# I2C2_1.0 register map
Vendor: Texas Instruments
Registers are 32-bit, read-write, no defined reset value unless marked. A register's access mark holds for its fields unless they carry their own. Offsets are as the file gives them; [hi:lo] are bit positions; lines under a group give offsets from that group; {n}, {i} and the like mark numbered series; 'fields as' and 'values as' point back to an identical list; <NAME> marks a mode.

## I2C2 (part 2 of 2)
0x800 I2C2_GPRCM group
  0x00 I2C2_PWREN — Power enable
    [0] ENABLE — Enable the power
      0=DISABLE (Disable Power); 1=ENABLE (Enable Power)
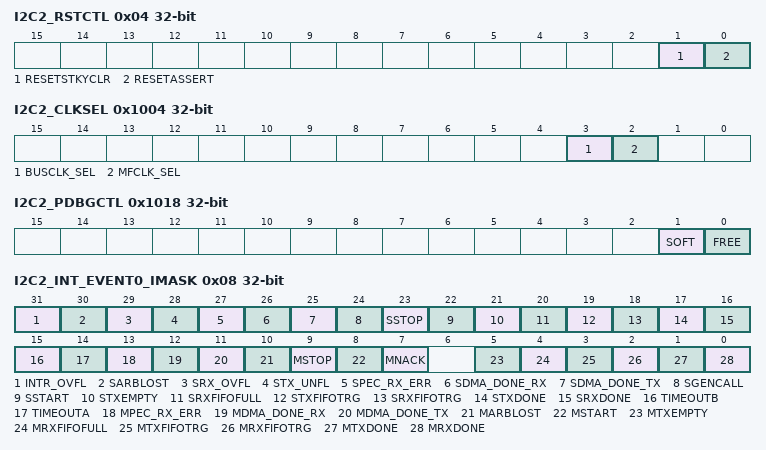
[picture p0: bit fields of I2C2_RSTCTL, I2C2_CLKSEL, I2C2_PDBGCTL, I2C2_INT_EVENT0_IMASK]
  0x04 I2C2_RSTCTL — Reset Control
    [1] RESETSTKYCLR — Clear the RESETSTKY bit in the STAT register
      0=NOP (Writing 0 has no effect); 1=CLR (Clear reset sticky bit)
    [0] RESETASSERT — Assert reset to the peripheral
      0=NOP (Writing 0 has no effect); 1=ASSERT (Assert reset)
  0x08 I2C2_CLKCFG — Peripheral Clock Configuration Register
    [8] BLOCKASYNC — Async Clock Request is blocked from starting SYSOSC or forcing bus clock to 32MHz
      0=DISABLE (Not block async clock request); 1=ENABLE (Block async clock request)
  0x14 I2C2_STAT ro — Status Register
    [16] RESETSTKY — This bit indicates, if the peripheral was reset, since this bit was cleared by RESETSTKYCLR in the RSTCTL register
      0=NORES (The peripheral has not been reset since this bit was last cleared by RESETSTKYCLR in the RSTCTL register); 1=RESET (The peripheral was reset since the last bit clear)
0x1000 I2C2_CLKDIV — Clock Divider
  [2:0] RATIO — Selects divide ratio of module clock
    0=DIV_BY_1 (Do not divide clock source); {v}=DIV_BY_{v+1} (Divide clock source by {v+1}) (v=1..7)
0x1004 I2C2_CLKSEL — Clock Select for Ultra Low Power peripherals
  [3] BUSCLK_SEL — Selects BUSCLK as clock source if enabled
    0=DISABLE (Does not select this clock as a source); 1=ENABLE (Select this clock as a source)
  [2] MFCLK_SEL — Selects MFCLK as clock source if enabled
    values as BUSCLK_SEL
0x1018 I2C2_PDBGCTL — Peripheral Debug Control
  [1] SOFT — Soft halt boundary control. This function is only available, if [FREE] is set to 'STOP'
    0=IMMEDIATE (The peripheral will halt immediately, even if the resultant state will result in corruption if the system is restarted); 1=DELAYED (The peripheral blocks the debug freeze until it has reached a boundary where it can resume without corruption)
  [0] FREE — Free run control
    0=STOP (The peripheral freezes functionality while the Core Halted input is asserted and resumes when it is deasserted.); 1=RUN (The peripheral ignores the state of the Core Halted input)
0x1020 I2C2_INT_EVENT0 group
  0x00 I2C2_INT_EVENT0_IIDX ro — Interrupt index
    [7:0] STAT — I2C Module Interrupt Vector Value. This register provides the highes priority interrupt index. A read clears the corresponding interrupt flag in RIS and MISC. 15h-1Fh = Reserved
      0=NO_INTR (No interrupt pending); 1=MRXDONEFG (Master data received); 2=MTXDONEFG (Master data transmitted); 3=MRXFIFOTRG (Master receive FIFO Trigger Level); 4=MTXFIFOTRG (Master transmit FIFO Trigger level); 5=MRXFIFOFULL (RX FIFO FULL Event/interrupt pending); 6=MTX_EMPTY (Transmit FIFO/Buffer Empty Event/interrupt pending); 8=MNACKFG (Address/Data NACK); 9=MSTARTFG (Start Event); 10=MSTOPFG (Stop Event); 11=MARBLOSTFG (Arbitration Lost); 12=MDMA_DONE_TX (DMA DONE on Channel TX); 13=MDMA_DONE_RX (DMA DONE on Channel RX); 14=MPEC_RX_ERR (Master PEC Receive Error Event); 15=TIMEOUTA (Timeout A Event); 16=TIMEOUTB (Timeout B Event); 17=SRXDONEFG (Slave Data Event); 18=STXDONEFG (Slave Data Event); 19=SRXFIFOTRG (Slave receive FIFO Trigger Level); 20=STXFIFOTRG (Slave transmit FIFO Trigger level); 21=SRXFIFOFULL (RX FIFO FULL Event/interrupt pending); 22=STXEMPTY (Transmit FIFO/Buffer Empty Event/interrupt pending); 23=SSTARTFG (Start Event); 24=SSTOPFG (Stop Event); 25=SGENCALL (General Call Event); 26=SDMA_DONE_TX (DMA DONE on Channel TX); 27=SDMA_DONE_RX (DMA DONE on Channel RX); 28=SPEC_RX_ERR (Slave PEC receive error event); 29=STX_UNFL (Slave TX FIFO underflow); 30=SRX_OVFL (Slave RX FIFO overflow event); 31=SARBLOST (Slave arbitration lost event); 32=INTR_OVFL (Interrupt overflow event)
  0x08 I2C2_INT_EVENT0_IMASK — Interrupt mask
    [31] INTR_OVFL — Interrupt Overflow Interrupt Mask
      0=CLR (Clear Interrupt Mask); 1=SET (Set Interrupt Mask)
    [30] SARBLOST — Slave Arbitration Lost
      0=CLR (Clear Set Interrupt Mask); 1=SET (Set Interrupt Mask)
    [29] SRX_OVFL — Slave RX FIFO overflow
      0=CLR (Clear Interrupt Mask); 1=SET (Set Interrupt Mask)
    [28] STX_UNFL — Slave TX FIFO underflow
      0=CLR (Clear Interrupt Mask); 1=SET (Set Interrupt Mask)
    [27] SPEC_RX_ERR — Slave RX Pec Error Interrupt
      0=CLR (Clear Interrupt Mask); 1=SET (Set Interrupt Mask)
    [26] SDMA_DONE_RX — Slave DMA Done on Event Channel RX
      0=CLR (Clear Interrupt Mask); 1=SET (Set Interrupt Mask)
    [25] SDMA_DONE_TX — Slave DMA Done on Event Channel TX
      0=CLR (Clear Interrupt Mask); 1=SET (Set Interrupt Mask)
    [24] SGENCALL — General Call Interrupt
      0=CLR (Clear Interrupt Mask); 1=SET (Set Interrupt Mask)
    [23] SSTOP — Stop Condition Interrupt
      0=CLR (Clear Interrupt Mask); 1=SET (Set Interrupt Mask)
    [22] SSTART — Start Condition Interrupt
      0=CLR (Clear Interrupt Mask); 1=SET (Set Interrupt Mask)
    [21] STXEMPTY — Slave Transmit FIFO Empty interrupt mask. This interrupt is set if all data in the Transmit FIFO have been shifted out and the transmit goes into idle mode.
      0=CLR (Clear Interrupt Mask); 1=SET (Set Interrupt Mask)
    [20] SRXFIFOFULL — RXFIFO full event. This interrupt is set if an Slave RX FIFO is full.
      0=CLR (Clear Interrupt Mask); 1=SET (Set Interrupt Mask)
    [19] STXFIFOTRG — Slave Transmit FIFO Trigger
      0=CLR (Clear Interrupt Mask); 1=SET (Set Interrupt Mask)
    [18] SRXFIFOTRG — Slave Receive FIFO Trigger
      0=CLR (Clear Interrupt Mask); 1=SET (Set Interrupt Mask)
    [17] STXDONE — Slave Transmit Transaction completed Interrupt
      0=CLR (Clear Interrupt Mask); 1=SET (Set Interrupt Mask)
    [16] SRXDONE — Slave Receive Data Interrupt Signals that a byte has been received
      0=CLR (Clear Interrupt Mask); 1=SET (Set Interrupt Mask)
    [15] TIMEOUTB — Timeout B Interrupt
      0=CLR (Clear Interrupt Mask); 1=SET (Set Interrupt Mask)
    [14] TIMEOUTA — Timeout A Interrupt
      0=CLR (Clear Interrupt Mask); 1=SET (Set Interrupt Mask)
    [13] MPEC_RX_ERR — Master RX Pec Error Interrupt
      0=CLR (Clear Interrupt Mask); 1=SET (Set Interrupt Mask)
    [12] MDMA_DONE_RX — DMA Done on Event Channel RX
      0=CLR (Interrupt disabled); 1=SET (Set Interrupt Mask)
    [11] MDMA_DONE_TX — DMA Done on Event Channel TX
      0=CLR (Interrupt disabled); 1=SET (Set Interrupt Mask)
    [10] MARBLOST — Arbitration Lost Interrupt
      0=CLR (Clear Interrupt Mask); 1=SET (Set Interrupt Mask)
    [9] MSTOP — STOP Detection Interrupt
      0=CLR (Clear Interrupt Mask); 1=SET (Set Interrupt Mask)
    [8] MSTART — START Detection Interrupt
      0=CLR (Clear Interrupt Mask); 1=SET (Set Interrupt Mask)
    [7] MNACK — Address/Data NACK Interrupt
      0=CLR (Clear Interrupt Mask); 1=SET (Set Interrupt Mask)
    [5] MTXEMPTY — Transmit FIFO Empty interrupt mask. This interrupt is set if all data in the Transmit FIFO have been shifted out and the transmit goes into idle mode.
      0=CLR (Clear Interrupt Mask); 1=SET (Set Interrupt Mask)
    [4] MRXFIFOFULL — RXFIFO full event. This interrupt is set if an RX FIFO is full.
      0=CLR (Clear Interrupt Mask); 1=SET (Set Interrupt Mask)
    [3] MTXFIFOTRG — Master Transmit FIFO Trigger Trigger when Transmit FIFO contains <= defined bytes
      0=CLR (Clear Interrupt Mask); 1=SET (Set Interrupt Mask)
    [2] MRXFIFOTRG — Master Receive FIFO Trigger Trigger when RX FIFO contains >= defined bytes
      0=CLR (Clear Interrupt Mask); 1=SET (Set Interrupt Mask)
    [1] MTXDONE — Master Transmit Transaction completed Interrupt
      0=CLR (Clear Interrupt Mask); 1=SET (Set Interrupt Mask)
    [0] MRXDONE — Master Receive Transaction completed Interrupt
      0=CLR (Clear Interrupt Mask); 1=SET (Set Interrupt Mask)
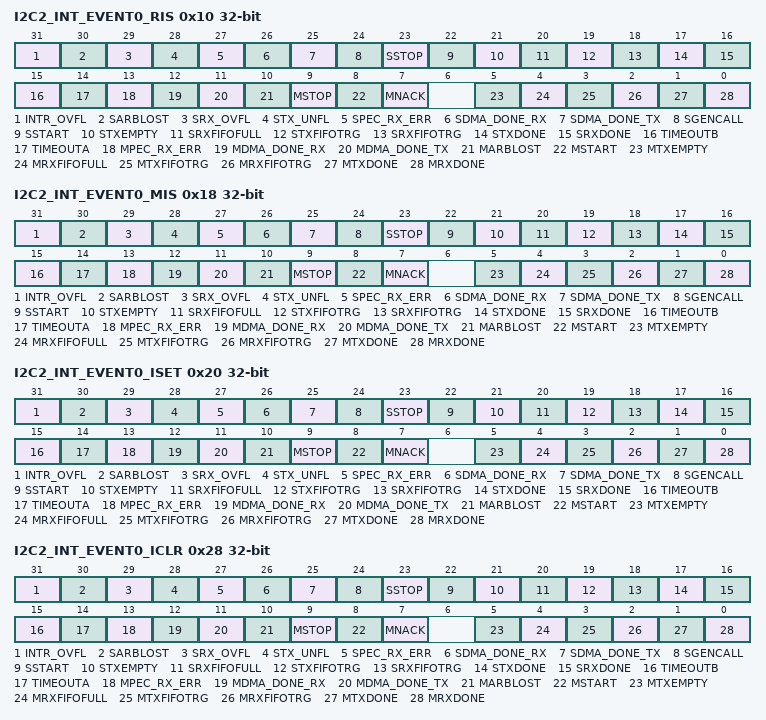
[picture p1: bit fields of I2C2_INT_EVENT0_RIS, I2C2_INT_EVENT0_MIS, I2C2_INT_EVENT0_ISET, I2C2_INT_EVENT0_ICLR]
  0x10 I2C2_INT_EVENT0_RIS — Raw interrupt status
    [31] INTR_OVFL — Interrupt overflow interrupt It is set when SSTART or SSTOP interrupts overflow i.e. occur twice without being serviced
      0=CLR (Interrupt did not occur); 1=SET (Interrupt occured)
    [30] SARBLOST — Slave Arbitration Lost
      0=CLR (Interrupt did not occur); 1=SET (Interrupt occured)
    [29] SRX_OVFL — Slave RX FIFO overflow
      0=CLR (Interrupt did not occur); 1=SET (Interrupt Occured)
    [28] STX_UNFL — Slave TX FIFO underflow
      0=CLR (Interrupt did not occur); 1=SET (Interrupt occured)
    [27] SPEC_RX_ERR — Slave RX Pec Error Interrupt
      0=CLR (Interrupt did not occur); 1=SET (Interrupt ocuured)
    [26] SDMA_DONE_RX — DMA Done on Event Channel RX
      0=CLR (Clear interrupt); 1=SET (Set interrupt)
    [25] SDMA_DONE_TX — DMA Done on Event Channel TX
      0=CLR (Clear interrupt); 1=SET (Set interrupt)
    [24] SGENCALL — General Call Interrupt
      0=CLR (Clear Interrupt Mask); 1=SET (Set Interrupt Mask)
    [23] SSTOP — Stop Condition Interrupt
      0=CLR (Clear Interrupt); 1=SET (Set interrupt)
    [22] SSTART — Start Condition Interrupt
      0=CLR (Clear interrupt); 1=SET (Set Interrupt)
    [21] STXEMPTY — Transmit FIFO Empty interrupt mask. This interrupt is set if all data in the Transmit FIFO have been shifted out and the transmit goes into idle mode.
      0=CLR (Interrupt did not occur); 1=SET (Set Interrupt Mask)
    [20] SRXFIFOFULL — RXFIFO full event. This interrupt is set if an RX FIFO is full.
      0=CLR (Clear Interrupt Mask); 1=SET (Set Interrupt Mask)
    [19] STXFIFOTRG — Slave Transmit FIFO Trigger
      0=CLR (Clear Interrupt Mask); 1=SET (Set Interrupt Mask)
    [18] SRXFIFOTRG — Slave Receive FIFO Trigger
      0=CLR (Clear Interrupt Mask); 1=SET (Set Interrupt Mask)
    [17] STXDONE — Slave Transmit Transaction completed Interrupt
      0=CLR (Interrupt did not occur); 1=SET (Set Interrupt Mask)
    [16] SRXDONE — Slave Receive Data Interrupt Signals that a byte has been received
      0=CLR (Interrupt did not occur); 1=SET (Set Interrupt Mask)
    [15] TIMEOUTB — Timeout B Interrupt
      0=CLR (Interrupt did not occur); 1=SET (Interrupt occured)
    [14] TIMEOUTA — Timeout A Interrupt
      0=CLR (Interrupt did not occur); 1=SET (Set Interrupt Mask)
    [13] MPEC_RX_ERR — Master RX Pec Error Interrupt
      0=CLR (Interrupt did not occur); 1=SET (Interrupt Occured)
    [12] MDMA_DONE_RX — DMA Done on Event Channel RX
      0=CLR (Interrupt disabled); 1=SET (Set Interrupt Mask)
    [11] MDMA_DONE_TX — DMA Done on Event Channel TX
      0=CLR (Interrupt disabled); 1=SET (Set Interrupt Mask)
    [10] MARBLOST — Arbitration Lost Interrupt
      0=CLR (Interrupt did not occur); 1=SET (Set Interrupt Mask)
    [9] MSTOP — STOP Detection Interrupt
      0=CLR (Interrupt did not occur); 1=SET (Set Interrupt Mask)
    [8] MSTART — START Detection Interrupt
      0=CLR (Interrupt did not occur); 1=SET (Set Interrupt Mask)
    [7] MNACK — Address/Data NACK Interrupt
      0=CLR (Interrupt did not occur); 1=SET (Set Interrupt Mask)
    [5] MTXEMPTY — Transmit FIFO Empty interrupt mask. This interrupt is set if all data in the Transmit FIFO have been shifted out and the transmit goes into idle mode.
      0=CLR (Interrupt did not occur); 1=SET (Set Interrupt Mask)
    [4] MRXFIFOFULL — RXFIFO full event. This interrupt is set if an RX FIFO is full.
      0=CLR (Interrupt did not occur); 1=SET (Set Interrupt Mask)
    [3] MTXFIFOTRG — Master Transmit FIFO Trigger Trigger when Transmit FIFO contains <= defined bytes
      0=CLR (Clear Interrupt Mask); 1=SET (Set Interrupt Mask)
    [2] MRXFIFOTRG — Master Receive FIFO Trigger Trigger when RX FIFO contains >= defined bytes
      0=CLR (Clear Interrupt Mask); 1=SET (Set Interrupt Mask)
    [1] MTXDONE — Master Transmit Transaction completed Interrupt
      0=CLR (Interrupt did not occur); 1=SET (Set Interrupt Mask)
    [0] MRXDONE — Master Receive Transaction completed Interrupt
      0=CLR (Interrupt did not occur); 1=SET (Set Interrupt Mask)
  0x18 I2C2_INT_EVENT0_MIS — Masked interrupt status
    [31] INTR_OVFL — Interrupt overflow
      0=CLR (Interrupt did not occur); 1=SET (Interrupt occured)
    [30] SARBLOST — Slave Arbitration Lost
      0=CLR (Clear interrupt mask); 1=SET (Set interrupt mask)
    [29] SRX_OVFL — Slave RX FIFO overflow
      0=CLR (Clear interrupt mask); 1=SET (Set interrupt mask)
    [28] STX_UNFL — Slave TX FIFO underflow
      0=CLR (Clear interrupt mask); 1=SET (Set interrupt mask)
    [27] SPEC_RX_ERR — Slave RX Pec Error Interrupt
      0=CLR (Clear interrupt mask); 1=SET (Set interrupt mask)
    [26] SDMA_DONE_RX — DMA Done on Event Channel RX
      0=CLR (Clear MIS); 1=SET (Set MIS)
    [25] SDMA_DONE_TX — DMA Done on Event Channel TX
      0=CLR (Clear MIS); 1=SET (Set MIS)
    [24] SGENCALL — General Call Interrupt
      0=CLR (Interrupt did not occur); 1=SET (Set Interrupt Mask)
    [23] SSTOP — Slave STOP Detection Interrupt
      0=CLR (Clear MIS); 1=SET (Set MIS)
    [22] SSTART — Slave START Detection Interrupt
      0=CLR (Clear MIS); 1=SET (Set MIS)
    [21] STXEMPTY — Transmit FIFO Empty interrupt mask. This interrupt is set if all data in the Transmit FIFO have been shifted out and the transmit goes into idle mode.
      0=CLR (Interrupt did not occur); 1=SET (Set Interrupt Mask)
    [20] SRXFIFOFULL — RXFIFO full event. This interrupt is set if an RX FIFO is full.
      0=CLR (Clear Interrupt Mask); 1=SET (Set Interrupt Mask)
    [19] STXFIFOTRG — Slave Transmit FIFO Trigger
      0=CLR (Clear Interrupt Mask); 1=SET (Set Interrupt Mask)
    [18] SRXFIFOTRG — Slave Receive FIFO Trigger
      0=CLR (Clear Interrupt Mask); 1=SET (Set Interrupt Mask)
    [17] STXDONE — Slave Transmit Transaction completed Interrupt
      0=CLR (Interrupt did not occur); 1=SET (Set Interrupt Mask)
    [16] SRXDONE — Slave Receive Data Interrupt Signals that a byte has been received
      0=CLR (Interrupt did not occur); 1=SET (Set Interrupt Mask)
    [15] TIMEOUTB — Timeout B Interrupt
      0=CLR (Clear interrupt mask); 1=SET (Set interrupt mask)
    [14] TIMEOUTA — Timeout A Interrupt
      0=CLR (Interrupt did not occur); 1=SET (Set Interrupt Mask)
    [13] MPEC_RX_ERR — Master RX Pec Error Interrupt
      0=CLR (Clear interrupt mask); 1=SET (Set interrupt mask)
    [12] MDMA_DONE_RX — DMA Done on Event Channel RX
      0=CLR (Interrupt disabled); 1=SET (Set Interrupt Mask)
    [11] MDMA_DONE_TX — DMA Done on Event Channel TX
      0=CLR (Interrupt disabled); 1=SET (Set Interrupt Mask)
    [10] MARBLOST — Arbitration Lost Interrupt
      0=CLR (Interrupt did not occur); 1=SET (Set Interrupt Mask)
    [9] MSTOP — STOP Detection Interrupt
      0=CLR (Interrupt did not occur); 1=SET (Set Interrupt Mask)
    [8] MSTART — START Detection Interrupt
      0=CLR (Interrupt did not occur); 1=SET (Set Interrupt Mask)
    [7] MNACK — Address/Data NACK Interrupt
      0=CLR (Interrupt did not occur); 1=SET (Set Interrupt Mask)
    [5] MTXEMPTY — Transmit FIFO Empty interrupt mask. This interrupt is set if all data in the Transmit FIFO have been shifted out and the transmit goes into idle mode.
      0=CLR (Interrupt did not occur); 1=SET (Set Interrupt Mask)
    [4] MRXFIFOFULL — RXFIFO full event. This interrupt is set if the RX FIFO is full.
      0=CLR (Interrupt did not occur); 1=SET (Set Interrupt Mask)
    [3] MTXFIFOTRG — Master Transmit FIFO Trigger Trigger when Transmit FIFO contains <= defined bytes
      0=CLR (Clear Interrupt Mask); 1=SET (Set Interrupt Mask)
    [2] MRXFIFOTRG — Master Receive FIFO Trigger Trigger when RX FIFO contains >= defined bytes
      0=CLR (Clear Interrupt Mask); 1=SET (Set Interrupt Mask)
    [1] MTXDONE — Master Transmit Transaction completed Interrupt
      0=CLR (Interrupt did not occur); 1=SET (Set Interrupt Mask)
    [0] MRXDONE — Master Receive Data Interrupt
      0=CLR (Interrupt did not occur); 1=SET (Set Interrupt Mask)
  0x20 I2C2_INT_EVENT0_ISET — Interrupt set
    [31] INTR_OVFL — Interrupt overflow
      0=NO_EFFECT; 1=SET (Set interrupt)
    [30] SARBLOST — Slave Arbitration Lost
      0=NO_EFFECT (Writing 0 has no effect); 1=SET (Set interrupt)
    [29] SRX_OVFL — Slave RX FIFO overflow
      0=NO_EFFECT (Writing 0 has no effect); 1=SET (Set interrupt)
    [28] STX_UNFL — Slave TX FIFO underflow
      0=NO_EFFECT (Writing 0 has no effect); 1=SET (Set interrupt)
    [27] SPEC_RX_ERR — Slave RX Pec Error Interrupt
      0=NO_EFFECT (Writing 0 has no effect); 1=SET (Set interrupt)
    [26] SDMA_DONE_RX — DMA Done on Event Channel RX
      0=NO_EFFECT (Writing 0 has no effect); 1=SET (Set interrupt)
    [25] SDMA_DONE_TX — DMA Done on Event Channel TX
      0=NO_EFFECT (Writing 0 has no effect); 1=SET (Set interrupt)
    [24] SGENCALL — General Call Interrupt
      0=NO_EFFECT (Writing 0 has no effect); 1=SET (Set Interrupt Mask)
    [23] SSTOP — Stop Condition Interrupt
      0=NO_EFFECT (Writing 0 has no effect); 1=SET (Set interrupt)
    [22] SSTART — Start Condition Interrupt
      0=NO_EFFECT (Writing 0 has no effect); 1=SET (Set interrupt)
    [21] STXEMPTY — Transmit FIFO Empty interrupt mask. This interrupt is set if all data in the Transmit FIFO have been shifted out and the transmit goes into idle mode.
      values as SGENCALL
    [20] SRXFIFOFULL — RXFIFO full event. This interrupt is set if an RX FIFO is full.
      0=NO_EFFECT (Clear Interrupt Mask); 1=SET (Set Interrupt Mask)
    [19] STXFIFOTRG — Slave Transmit FIFO Trigger
      values as SRXFIFOFULL
    [18] SRXFIFOTRG — Slave Receive FIFO Trigger
      values as SRXFIFOFULL
    [17] STXDONE — Slave Transmit Transaction completed Interrupt
      values as SGENCALL
    [16] SRXDONE — Slave Receive Data Interrupt Signals that a byte has been received
      values as SGENCALL
    [15] TIMEOUTB — Timeout B Interrupt
      0=NO_EFFECT (Writing 0 has no effect); 1=SET (Set interrupt)
    [14] TIMEOUTA — Timeout A interrupt
      values as SGENCALL
    [13] MPEC_RX_ERR — Master RX Pec Error Interrupt
      0=NO_EFFECT (Writing 0 has no effect); 1=SET (Set interrupt)
    [12] MDMA_DONE_RX — DMA Done on Event Channel RX
      0=NO_EFFECT (Interrupt disabled); 1=SET (Set Interrupt Mask)
    [11] MDMA_DONE_TX — DMA Done on Event Channel TX
      0=NO_EFFECT (Interrupt disabled); 1=SET (Set Interrupt Mask)
    [10] MARBLOST — Arbitration Lost Interrupt
      values as SGENCALL
    [9] MSTOP — STOP Detection Interrupt
      values as SGENCALL
    [8] MSTART — START Detection Interrupt
      values as SGENCALL
    [7] MNACK — Address/Data NACK Interrupt
      values as SGENCALL
    [5] MTXEMPTY — Transmit FIFO Empty interrupt mask. This interrupt is set if all data in the Transmit FIFO have been shifted out and the transmit goes into idle mode.
      values as SGENCALL
    [4] MRXFIFOFULL — RXFIFO full event.
      values as SGENCALL
    [3] MTXFIFOTRG — Master Transmit FIFO Trigger Trigger when Transmit FIFO contains <= defined bytes
      values as SRXFIFOFULL
    [2] MRXFIFOTRG — Master Receive FIFO Trigger Trigger when RX FIFO contains >= defined bytes
      values as SRXFIFOFULL
    [1] MTXDONE — Master Transmit Transaction completed Interrupt
      values as SGENCALL
    [0] MRXDONE — Master Receive Data Interrupt Signals that a byte has been received
      values as SGENCALL
  0x28 I2C2_INT_EVENT0_ICLR — Interrupt clear
    [31] INTR_OVFL — Interrupt overflow
      0=NO_EFFECT; 1=CLR (Clear interrupt)
    [30] SARBLOST — Slave Arbitration Lost
      0=NO_EFFECT (Writing 0 has no effect); 1=CLR (Clear Interrupt)
    [29] SRX_OVFL — Slave RX FIFO overflow
      values as SARBLOST
    [28] STX_UNFL — Slave TX FIFO underflow
      values as SARBLOST
    [27] SPEC_RX_ERR — Slave RX Pec Error Interrupt
      values as SARBLOST
    [26] SDMA_DONE_RX — DMA Done on Event Channel RX
      0=NO_EFFECT (Writing 0 has no effect); 1=CLR (Clear interrupt)
    [25] SDMA_DONE_TX — DMA Done on Event Channel TX
      values as SDMA_DONE_RX
    [24] SGENCALL — General Call Interrupt
      0=NO_EFFECT (Writing 0 has no effect); 1=CLR (Set Interrupt Mask)
    [23] SSTOP — Slave STOP Detection Interrupt
      values as SDMA_DONE_RX
    [22] SSTART — Slave START Detection Interrupt
      values as SDMA_DONE_RX
    [21] STXEMPTY — Transmit FIFO Empty interrupt mask. This interrupt is set if all data in the Transmit FIFO have been shifted out and the transmit goes into idle mode.
      values as SGENCALL
    [20] SRXFIFOFULL — RXFIFO full event. This interrupt is set if an RX FIFO is full.
      0=NO_EFFECT (Clear Interrupt Mask); 1=CLR (Set Interrupt Mask)
    [19] STXFIFOTRG — Slave Transmit FIFO Trigger
      values as SRXFIFOFULL
    [18] SRXFIFOTRG — Slave Receive FIFO Trigger
      values as SRXFIFOFULL
    [17] STXDONE — Slave Transmit Transaction completed Interrupt
      values as SGENCALL
    [16] SRXDONE — Slave Receive Data Interrupt Signals that a byte has been received
      values as SGENCALL
    [15] TIMEOUTB — Timeout B Interrupt
      values as SARBLOST
    [14] TIMEOUTA — Timeout A interrupt
      values as SGENCALL
    [13] MPEC_RX_ERR — Master RX Pec Error Interrupt
      values as SARBLOST
    [12] MDMA_DONE_RX — DMA Done on Event Channel RX
      0=NO_EFFECT (Interrupt disabled); 1=CLR (Set Interrupt Mask)
    [11] MDMA_DONE_TX — DMA Done on Event Channel TX
      0=NO_EFFECT (Interrupt disabled); 1=CLR (Set Interrupt Mask)
    [10] MARBLOST — Arbitration Lost Interrupt
      values as SGENCALL
    [9] MSTOP — STOP Detection Interrupt
      values as SGENCALL
    [8] MSTART — START Detection Interrupt
      values as SGENCALL
    [7] MNACK — Address/Data NACK Interrupt
      values as SGENCALL
    [5] MTXEMPTY — Transmit FIFO Empty interrupt mask. This interrupt is set if all data in the Transmit FIFO have been shifted out and the transmit goes into idle mode.
      values as SGENCALL
    [4] MRXFIFOFULL — RXFIFO full event.
      values as SGENCALL
    [3] MTXFIFOTRG — Master Transmit FIFO Trigger Trigger when Transmit FIFO contains <= defined bytes
      values as SRXFIFOFULL
    [2] MRXFIFOTRG — Master Receive FIFO Trigger Trigger when RX FIFO contains >= defined bytes
      values as SRXFIFOFULL
    [1] MTXDONE — Master Transmit Transaction completed Interrupt
      values as SGENCALL
    [0] MRXDONE — Master Receive Data Interrupt Signals that a byte has been received
      values as SGENCALL
0x1050 I2C2_INT_EVENT1 group
  0x00 I2C2_INT_EVENT1_IIDX ro — Interrupt index
    [7:0] STAT — I2C Module Interrupt Vector Value. This register provides the highes priority interrupt index. A read clears the corresponding interrupt flag in RIS and MISC. 15h-1Fh = Reserved
      0=NO_INTR (No interrupt pending); 1=MRXFIFOTRG (Master receive FIFO Trigger Level); 2=MTXFIFOTRG (Master transmit FIFO Trigger level); 3=SRXFIFOTRG (Slave receive FIFO Trigger Level); 4=STXFIFOTRG (Slave transmit FIFO Trigger level)
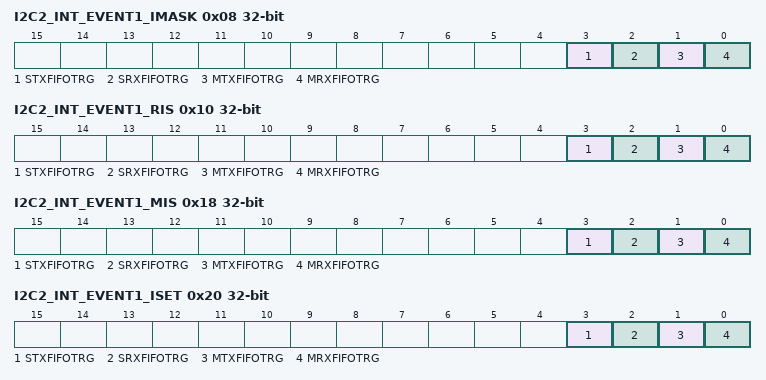
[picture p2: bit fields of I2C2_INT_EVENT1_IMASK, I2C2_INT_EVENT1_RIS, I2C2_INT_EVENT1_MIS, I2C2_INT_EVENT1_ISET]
  0x08 I2C2_INT_EVENT1_IMASK — Interrupt mask
    [all] fields
      0=CLR (Clear Interrupt Mask); 1=SET (Set Interrupt Mask)
    [3] STXFIFOTRG — Slave Transmit FIFO Trigger
    [2] SRXFIFOTRG — Slave Receive FIFO Trigger
    [1] MTXFIFOTRG — Master Transmit FIFO Trigger Trigger when Transmit FIFO contains <= defined bytes
    [0] MRXFIFOTRG — Master Receive FIFO Trigger Trigger when RX FIFO contains >= defined bytes
  0x10 I2C2_INT_EVENT1_RIS — Raw interrupt status
    fields as I2C2_INT_EVENT1.I2C2_INT_EVENT1_IMASK
  0x18 I2C2_INT_EVENT1_MIS — Masked interrupt status
    fields as I2C2_INT_EVENT1.I2C2_INT_EVENT1_IMASK
  0x20 I2C2_INT_EVENT1_ISET — Interrupt set
    [all] fields
      values as I2C2_INT_EVENT0.I2C2_INT_EVENT0_ISET.SRXFIFOFULL
    [3] STXFIFOTRG — Slave Transmit FIFO Trigger
    [2] SRXFIFOTRG — Slave Receive FIFO Trigger
    [1] MTXFIFOTRG — Master Transmit FIFO Trigger Trigger when Transmit FIFO contains <= defined bytes
    [0] MRXFIFOTRG — Master Receive FIFO Trigger Trigger when RX FIFO contains >= defined bytes
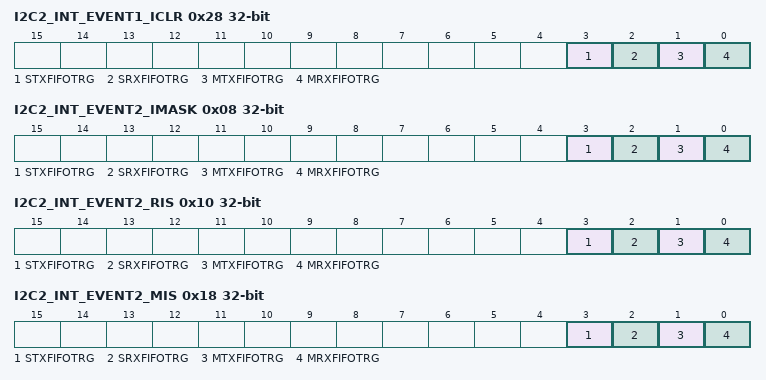
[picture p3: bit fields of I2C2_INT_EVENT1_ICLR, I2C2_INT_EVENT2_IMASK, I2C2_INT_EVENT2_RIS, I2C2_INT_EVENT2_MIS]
  0x28 I2C2_INT_EVENT1_ICLR — Interrupt clear
    [all] fields
      values as I2C2_INT_EVENT0.I2C2_INT_EVENT0_ICLR.SRXFIFOFULL
    [3] STXFIFOTRG — Slave Transmit FIFO Trigger
    [2] SRXFIFOTRG — Slave Receive FIFO Trigger
    [1] MTXFIFOTRG — Master Transmit FIFO Trigger Trigger when Transmit FIFO contains <= defined bytes
    [0] MRXFIFOTRG — Master Receive FIFO Trigger Trigger when RX FIFO contains >= defined bytes
0x1080 I2C2_INT_EVENT2 group
  0x00 I2C2_INT_EVENT2_IIDX ro — Interrupt index
    fields as I2C2_INT_EVENT1.I2C2_INT_EVENT1_IIDX
  0x08 I2C2_INT_EVENT2_IMASK — Interrupt mask
    fields as I2C2_INT_EVENT1.I2C2_INT_EVENT1_IMASK
  0x10 I2C2_INT_EVENT2_RIS — Raw interrupt status
    fields as I2C2_INT_EVENT1.I2C2_INT_EVENT1_IMASK
  0x18 I2C2_INT_EVENT2_MIS — Masked interrupt status
    fields as I2C2_INT_EVENT1.I2C2_INT_EVENT1_IMASK
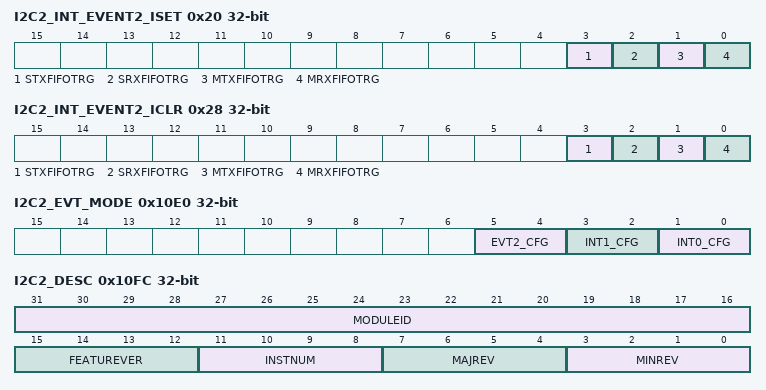
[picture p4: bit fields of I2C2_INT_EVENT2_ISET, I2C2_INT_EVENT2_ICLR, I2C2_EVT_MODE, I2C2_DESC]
  0x20 I2C2_INT_EVENT2_ISET — Interrupt set
    fields as I2C2_INT_EVENT1.I2C2_INT_EVENT1_ISET
  0x28 I2C2_INT_EVENT2_ICLR — Interrupt clear
    fields as I2C2_INT_EVENT1.I2C2_INT_EVENT1_ICLR
0x10E0 I2C2_EVT_MODE ro — Event Mode
  [all] fields
    0=DISABLE (The interrupt or event line is disabled.); 1=SOFTWARE (The interrupt or event line is in software mode. Software must clear the RIS.); 2=HARDWARE (The interrupt or event line is in hardware mode. The hardware (another module) clears automatically the associated RIS flag.)
  [5:4] EVT2_CFG — Event line mode select for event corresponding to [IPSTANDARD.INT_EVENT2]
  [3:2] INT1_CFG — Event line mode select for event corresponding to [IPSTANDARD.INT_EVENT1]
  [1:0] INT0_CFG — Event line mode select for event corresponding to [IPSTANDARD.INT_EVENT0]
0x10E4 I2C2_INTCTL — Interrupt control register
  [0] INTEVAL — Writing a 1 to this field re-evaluates the interrupt sources.
    0=DISABLE (The interrupt or event line is disabled.); 1=EVAL (The interrupt or event line is in software mode. Software must clear the RIS.)
0x10FC I2C2_DESC — Module Description
  [31:16] MODULEID — Module identification contains a unique peripheral identification number. The assignments are maintained in a central database for all of the platform modules to ensure uniqueness.
    0=MINIMUM (Smallest value); 0xFFFF=MAXIMUM (Highest possible value)
  [15:12] FEATUREVER — Feature Set for the module *instance*
    0=MINIMUM (Smallest value); 15=MAXIMUM (Highest possible value)
  [11:8] INSTNUM — Instance Number within the device. This will be a parameter to the RTL for modules that can have multiple instances
    values as FEATUREVER
  [7:4] MAJREV — Major rev of the IP
    values as FEATUREVER
  [3:0] MINREV — Minor rev of the IP
    values as FEATUREVER
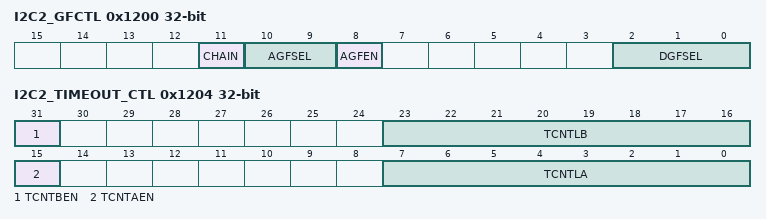
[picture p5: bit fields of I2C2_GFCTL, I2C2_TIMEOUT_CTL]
0x1200 I2C2_GFCTL — I2C Glitch Filter Control
  [11] CHAIN — Analog and digital noise filters chaining enable.
    0=DISABLE (When 0, chaining is disabled and only digital filter output is available to IP logic for oversampling); 1=ENABLE (When 1, analog and digital glitch filters are chained and the output of the combination is made available to IP logic for oversampling)
  [10:9] AGFSEL — Analog Glitch Suppression Pulse Width This field controls the pulse width select for the analog glitch suppression on SCL and SDA lines. See device datasheet for exact values. (ULP I2C only)
    0=AGLIT_5 (Pulses shorter then 5ns length are filtered.); 1=AGLIT_10 (Pulses shorter then 10ns length are filtered.); 2=AGLIT_25 (Pulses shorter then 25ns length are filtered.); 3=AGLIT_50 (Pulses shorter then 50ns length are filtered.)
  [8] AGFEN — Analog Glitch Suppression Enable
    0=DISABLE (Analog Glitch Filter disable); 1=ENABLE (Analog Glitch Filter enable)
  [2:0] DGFSEL — Glitch Suppression Pulse Width This field controls the pulse width select for glitch suppression on the SCL and SDA lines. The following values are the glitch suppression values in terms of functional clocks. (Core Domain only)
    0=DISABLED (Bypass); 1=CLK_1 (1 clock); 2=CLK_2 (2 clocks); 3=CLK_3 (3 clocks); 4=CLK_4 (4 clocks); 5=CLK_8 (8 clocks); 6=CLK_16 (16 clocks); 7=CLK_31 (31 clocks)
0x1204 I2C2_TIMEOUT_CTL — I2C Timeout Count Control Register
  [31] TCNTBEN — Timeout Counter B Enable
    0=DISABLE (Disable Timeout Counter B); 1=ENABLE (Enable Timeout Counter B)
  [23:16] TCNTLB — Timeout Count B Load: Counter B is used for SCL High Detection. This field contains the upper 8 bits of a 12-bit pre-load value for the Timeout B count. NOTE: The value of CNTLB must be greater than 1h. Each count is equal to 1* clock period. For example, with 10MHz functional clock one timeout period will be equal to1*100ns.
    0=MINIMUM (Smallest possible value); 255=MAXIMUM (Highest possible value)
  [15] TCNTAEN — Timeout Counter A Enable
    values as TCNTBEN
  [7:0] TCNTLA — Timeout counter A load value Counter A is used for SCL low detection. This field contains the upper 8 bits of a 12-bit pre-load value for the Timeout A count. NOTE: The value of CNTLA must be greater than 1h. Each count is equal to 520 times the timeout period of functional clock. For example, with 8MHz functional clock and a 100KHz operating I2C clock, one timeout period will be equal to (1 / 8MHz) * 520 or 65 us.
    0=MINIMUM (Smallest Value); 255=MAXIMUM (Highest possible value)
